# R7FA8M1AH register map
Vendor: Renesas; Series: RA8; File version: 1.2
CPU: CM85 r0p0, little endian, MPU, FPU, VTOR, 4 interrupt priority bits
Registers are 32-bit, read-write, reset 0x0 unless marked. A register's access mark holds for its fields unless they carry their own. Offsets are from the block's base; [hi:lo] are bit positions; {n}, {i} and the like mark numbered series; 'fields as' and 'values as' point back to an identical list.

## DRW — 2D Drawing Engine
Base 0x40344000
Same registers: DRW_NS 0x50344000
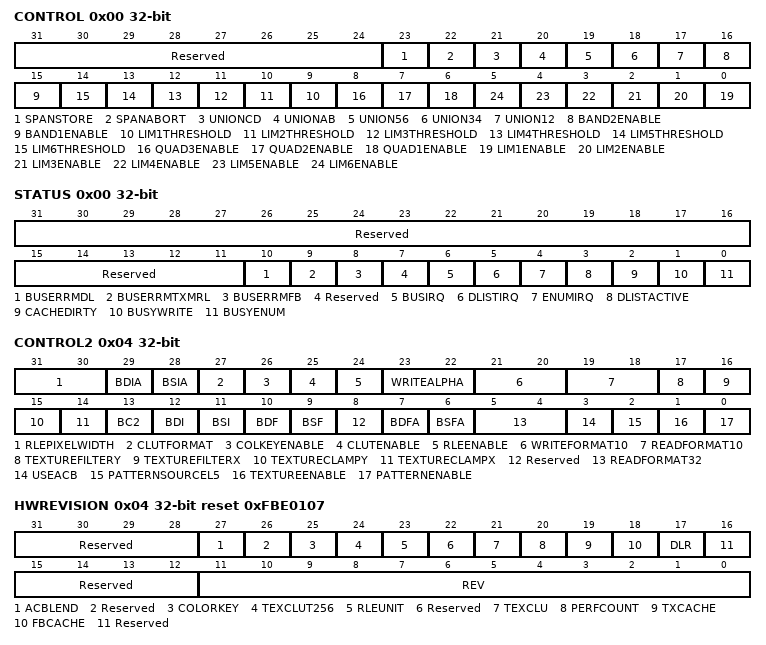
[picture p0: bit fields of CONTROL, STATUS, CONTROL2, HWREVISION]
0x00 CONTROL wo — Geometry Control Register
  [31:24] Reserved — The write value should be 00000000.
  [23] SPANSTORE — Nextline span start is always equal or left to current-line span start
    0=disabled; 1=enabled
  [22] SPANABORT — Shape is horizontally convex, only a single span per scanline
    0=disabled; 1=enabled
  [21] UNIONCD — Combine outputs C & D as union (output is final)
    0=minimum/intersect; 1=maximum/union
  [20] UNIONAB — Combine outputs A & B as union (output is called C)
    0=minimum/intersect; 1=maximum/union
  [19] UNION56 — Combine limter 5 & 6 as union (output is called D)
    0=minimum/intersect; 1=maximum/union
  [18] UNION34 — Combine limter 3 & 4 as union (output is called B)
    0=minimum/intersect; 1=maximum/union
  [17] UNION12 — Combine limter 1 & 2 as union (output is called A)
    0=minimum/intersect; 1=maximum/union
  [16] BAND2ENABLE — Enable band postprocess for limiter 1 (see L1BAND)
    0=disabled; 1=enabled
  [15] BAND1ENABLE — Enable band postprocess for limiter 1 (see L1BAND)
    0=disabled; 1=enabled
  [n+8] LIM{n}THRESHOLD (n=1..6) — Enable limiter {n} threshold mode
    0=disabled; 1=enabled
  [8] QUAD3ENABLE — Enable quadratic coupling of limiters 5 and 6
    0=disabled; 1=enabled
  [7] QUAD2ENABLE — Enable quadratic coupling of limiters 3 and 4
    0=disabled; 1=enabled
  [6] QUAD1ENABLE — Enable quadratic coupling of limiters 1 and 2
    0=disabled; 1=enabled
  [n-1] LIM{n}ENABLE (n=1..6) — Enable limiter {n}
    0=disabled; 1=enabled
0x00 STATUS ro (alternate view of CONTROL) — Status Control Register
  [31:16] Reserved — These bits are read as 0000000000000000.
  [15:11] Reserved — These bits are read as 00000.
  [10] BUSERRMDL — display list bus error interrupt triggered
    0=no display list bus error occurred or interrupt disabled; 1=display list bus error interrupt triggered
  [9] BUSERRMTXMRL — texture bus error interrupt triggered
    0=no texture bus error occurred or interrupt disabled; 1=texture bus error interrupt triggered
  [8] BUSERRMFB — framebuffer bus error interrupt triggered
    0=no framebuffer bus error occured or interrupt disabled; 1=framebuffer bus error interrupt triggered
  [7] Reserved — This bit is read as 0.
  [6] BUSIRQ — bus error interrupt triggered
    0=no bus error occurred or interrupt disabled; 1=bus error interrupt triggered
  [5] DLISTIRQ — display list finished interrupt triggered
    0=display list not finished or interrupt disabled; 1=display list finished interrupt triggered
  [4] ENUMIRQ — enumeration finished interrupt triggered
    0=enumeration not finished or interrupt disabled; 1=enumeration finished interrupt triggered
  [3] DLISTACTIVE — Display list reader status
    0=display list reader is idle; 1=display list reader busy, no direct write access to registers allowed
  [2] CACHEDIRTY — Framebuffer cache status
    0=framebuffer cache is not dirty; 1=framebuffer cache is dirty, frame should not be flipped
  [1] BUSYWRITE — Framebuffer writeback status
    0=framebuffer writeback finished; 1=framebuffer writeback busy, framebuffer type can not be changed
  [0] BUSYENUM — Enumeration unit status
    0=enumeration unit idle; 1=enumeration unit busy, new primitive can not be started
0x04 CONTROL2 wo — Surface Control Register
  [31:30] RLEPIXELWIDTH — Texel width for RLE unit
    {v}={v+1} byte per texel (v=0..3)
  [29] BDIA — Blend destination factor inverted in alpha channel (USEACB = 1)
    0=use blend factor as specified through BDFA; 1=invert blend destination factor (1-x)
  [28] BSIA — Blend source factor inverted in alpha channel (USEACB = 1)
    0=use blend factor as specified through BSFA; 1=invert blend source factor (1-x)
  [27] CLUTFORMAT — Format of the CLUT
    0=aRGB(8888); 1=RGB(565)
  [26] COLKEYENABLE — color keying enable
    0=color keying disabled; 1=color keying enabled
  [25] CLUTENABLE
    0=CLUT disabled; 1=CLUT enabled
  [24] RLEENABLE
    0=RLE disabled; 1=RLE enabled
  [23:22] WRITEALPHA — Writeback alpha source for framebufferSet the 'alpha source' for the framebuffer(USEACB = 0)Blend alpha in color 2 instead of framebuffer alpha((USEACB = 1))In not alpha channel blending mode (USEACB = 0):Set the 'alpha source' for the framebuffer.In alpha channel blending mode (USEACB = 1):Blend alpha in color 2 instead of framebuffer alpha00B: BC2A = 1: use alpha from framebuffer as destination (DST_A)else: BC2A = 0: use alpha in color 2 as destination (DST_A)
    0=use alpha from color 2; 1=use source alpha (pixel coverage); 2=use 0.0 as alpha; 3=use alpha from framebuffer
  [21:20] WRITEFORMAT10 — Pixel format of the framebuffer
    0=8bpp a(8)0; 1=16bpp RGB(565); 2=32bpp aRGB(8888); 3=16bpp aRGB(4444)
  [19:18] READFORMAT10 — Pixel format of the texture buffer{READFORMAT32,READFORMAT10}0000: 8 bpp a(8)0001: 16 bpp RGB(565)0010: 32 bpp aRGB(8888)0011: 16 bpp aRGB(4444)0100: 16 bpp aRGB(1555)0101: 8 bpp aCLUT(44) 4 bit alpha and 4 bit indexed color1001: 8 bpp CLUT(8)/I(8), 8 bit indexed color/luminance1010: 4 bpp CLUT(4)/I(4), 4 bit indexed color/luminance1011: 2 bpp CLUT(2)/I(2), 2 bit indexed color/luminance 1100: 1 bpp CLUT(1)/I(1), 1 bit indexed color/luminance
    0=8 bpp a(8) (READFORMAT32=00) / 16 bpp aRGB(1555) (READFORMAT32=01) / 1 bpp CLUT(1)/I(1), 1 bit indexed color/luminance (READFORMAT32=11); 1=16 bpp RGB(565) (READFORMAT32=00) / 8 bpp aCLUT(44) 4 bit alpha and 4 bit indexed color (READFORMAT32=01) / 8 bpp CLUT(8)/I(8), 8 bit indexed color/luminance (READFORMAT32=10); 2=32 bpp aRGB(8888) (READFORMAT32=00) / 4 bpp CLUT(4)/I(4), 4 bit indexed color/luminance (READFORMAT32=10); 3=16 bpp aRGB(4444) (READFORMAT32=00) / 2 bpp CLUT(2)/I(2), 2 bit indexed color/luminance (READFORMAT32=10)
  [17] TEXTUREFILTERY — Linear filtering on texture V axis
    0=no filtering on texture V axis; 1=linear filtering on texture V axis
  [16] TEXTUREFILTERX — Linear filtering on texture U axis
    0=no filtering on texture U axis; 1=linear filtering on texture U axis
  [15] TEXTURECLAMPY — Calculating V limiter outside use textureThe bit describes what happens if the V limiter (y direction in texture space) calculates a V value outside of the used texture
    0=Texture wrap mode: The integer part of the calculated value from the v limiter is anded with TEXVMASK. This results in a repetition of the texture in y/v direction.; 1=Texture clamp mode: The texture color at the border of the texture is taken. This results in a repetition of the texture border color in y/v direction.
  [14] TEXTURECLAMPX — Calculating U limiter outside use textureThe bit describes what happens if the U limiter (x direction in texture space) calculates a U value outside of the used texture
    0=Texture wrap mode: The integer part of the calculated value from the u limiter is anded with TEXUMASK. This results in a repetition of the texture in x/u direction.; 1=Texture clamp mode: The texture color at the border of the texture is taken. This results in a repetition of the texture border color in x/u direction.
  [13] BC2 — Blend color 2 instead of framebuffer pixel
    0=use pixel from framebuffer as destination (DST); 1=use color 2 as destination (DST)
  [12] BDI — Blend destination factor is inverteddst factor will be inverted (meaning 1-a or 1-1 depending on BDF)
    0=use blend factor as specified through BDF; 1=invert blend destinationfactor (1-x)
  [11] BSI — Blend source factor is invertedsrc factor will be inverted (meaning 1-a or 1-1 depending on BSF)
    0=use blend factor as specified through BSF; 1=invert blend source factor (1-x)
  [10] BDF — Blend destination factordst factor is alpha (factor is 1 per default)
    0=use 1.0 as blend destination factor; 1=use alpha as blend destination factor
  [9] BSF — Blend source factorsrc factor is alpha (factor is 1 per default)
    0=use 1.0 as blend source factor; 1=use alpha as blend source factor
  [8] Reserved — The write value should be 0.
  [7] BDFA — Blend destinetion factor for alpha channel in alpha channel blending mode (USEACB = 1)
    0=use 1.0 as blend destination factor for alpha channel; 1=use alpha as blend destination factor for alpha channel
  [6] BSFA — Blend source factor for alpha channel in alpha channel blending mode (USEACB = 1)
    0=use 1.0 as blend source factor for alpha channel; 1=use alpha as blend source factor for alpha channel
  [5:4] READFORMAT32 — Bit 4 and 3 of the texture buffer format.See READFORMAT above for description
  [3] USEACB — Alpha blend mode
    0=use WRITEALPHA[1:0] mode; 1=use full alpha channel blending mode
  [2] PATTERNSOURCEL5 — Limiter 5 is used as pattern index instead of the default U limiter.Limiter 5 can be combined with limiter 6 to form a quadratic limiter which can be used to make quadratic pattern functions to draw radial patterns.
  [1] TEXTUREENABLE — Pixel source is read from texture and used as an alpha to blend between COLOR1 and COLOR2
    0=disabled texture; 1=enabled texture
  [0] PATTERNENABLE — Pixel source is a pattern color (blend of COLOR1 and COLOR2 depending on PATTERN and pattern index)
    0=disabled pattern; 1=enabled pattern
0x04 HWREVISION ro reset 0xFBE0107 (reset mask 0xFFFFF000) (alternate view of CONTROL2) — Hardware Version and Feature Set ID Register
  [31:28] Reserved — These bits are read as 0000.
  [27] ACBLEND — Alpha channel blending feature
    0=Alpha channel blending unavailable; 1=Alpha channel blending available
  [26] Reserved — This bit is read as 1.
  [25] COLORKEY — Colorkey feature
    0=Colorkey unavailable; 1=Colorkey available
  [24] TEXCLUT256 — Texture CLUT feature
    0=Texture CLUT unavailable; 1=Texture CLUT available
  [23] RLEUNIT — RLE unit feature
    0=RLE unit unavailable; 1=RLE unit available
  [22] Reserved — This bit is read as 0.
  [21] TEXCLU — Texture CLUT with 16 or 256 entries feature
    0=Texture CLUT with 16 or 256 entries unavailable; 1=Texture CLUT with 16 or 256 entries available
  [20] PERFCOUNT — Two performance counter feature
    0=Two performance counter unavailable; 1=Two performance counter available
  [19] TXCACHE — Texture cache feature
    0=Texture cache unavailable; 1=Texture cache available
  [18] FBCACHE — Framebuffer cache feature
    0=Framebuffer cache unavailable; 1=Framebuffer cache available
  [17] DLR — Display list reader feature
    0=Display list reader unavailable; 1=Display list reader available
  [16] Reserved — This bit is read as 0.
  [15:12] Reserved — These bits are read as 0000.
  [11:0] REV — Revision number
{0xC+4i} L{i}START (i=1..6) wo — Limiter {i} Start Value Register
  [31:0] LSTART — Start value of the n'th limiter(n=1-6)
{0x24+4i} L{i}XADD (i=1..6) wo — Limiter {i} X-Axis Increment Register
  [31:0] LXADD — X-axis increment
{0x3C+4i} L{i}YADD (i=1..6) wo — Limiter {i} Y-Axis Increment Register
  [31:0] LYADD — Y-axis increment
{0x54+4i} L{i}BAND (i=1..2) wo — Limiter {i} Band Width Parameter Register
  [31:0] LBAND — Limiter m band width parameter
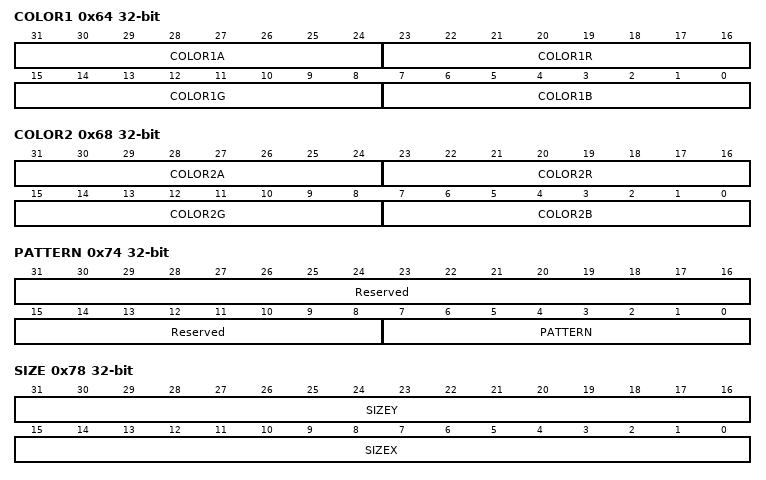
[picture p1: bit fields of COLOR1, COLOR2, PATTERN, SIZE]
0x64 COLOR1 wo — Base Color Register
  [31:24] COLOR1A — Alpha channel of color 1(0x00: transparent. . . 0xFF: opaque)
  [23:16] COLOR1R — Red channel of color 1
  [15:8] COLOR1G — Green channel of color 1
  [7:0] COLOR1B — Blue channel of color 1
0x68 COLOR2 wo — Secondary Color Register
  [31:24] COLOR2A — Alpha channel of color 2(0x00: transparent. . . 0xFF: opaque)
  [23:16] COLOR2R — Red channel of color 2
  [15:8] COLOR2G — Green channel of color 2
  [7:0] COLOR2B — Blue channel of color 2
0x74 PATTERN wo
  [31:16] Reserved — The write value should be 0000000000000000.
  [15:8] Reserved — The write value should be 00000000.
  [7:0] PATTERN — Bitmap of the pattern
0x78 SIZE wo — Bounding Box Dimension Register
  [31:16] SIZEY — Height of the bounding box in pixelsvalid range: 0 to 1024
  [15:0] SIZEX — Width of the bounding box in pixelsvalid range: 0 to 1024
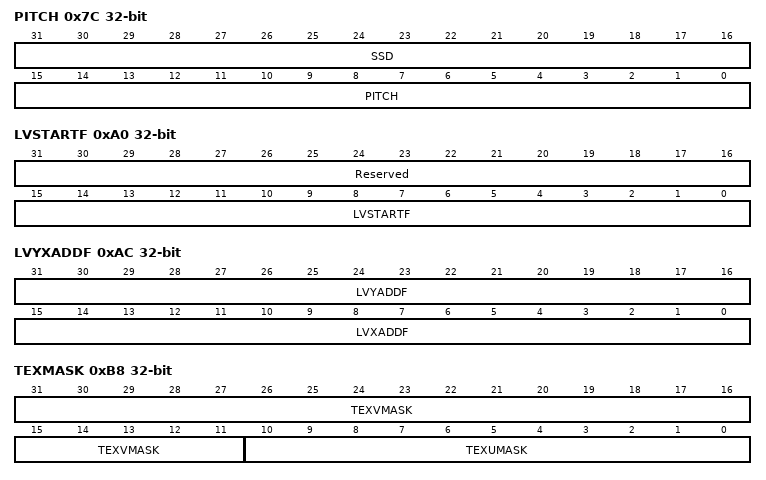
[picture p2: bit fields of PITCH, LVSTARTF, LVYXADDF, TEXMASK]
0x7C PITCH wo — Framebuffer Pitch And Spanstore Delay Register
  [31:16] SSD — Spanstore delay
  [15:0] PITCH — pitch of the framebuffer. A negative width can be used to render bottom-up instead of top-down
0x80 ORIGIN wo — Framebuffer Base Address Register
  [31:0] ORIGIN — Address of the first pixel in framebuffer
0x90 LUSTART wo — U Limiter Start Value Register
  [31:0] LUSTART — U limiter start value
0x94 LUXADD wo — U Limiter X-Axis Increment Register
  [31:0] LUXADD — U limiter x-axis increment
0x98 LUYADD wo — U Limiter Y-Axis Increment Register
  [31:0] LUYADD — U limiter y-axis increment
0x9C LVSTARTI wo — V Limiter Start Value Integer Part Register
  [31:0] LVSTARTI — V limiter start value integer part
0xA0 LVSTARTF wo — V Limiter Start Value Fractional Part Register
  [31:16] Reserved — The write value should be 0000000000000000.
  [15:0] LVSTARTF — V limiter start value fractional part
0xA4 LVXADDI wo — V Limiter X-Axis Increment Integer Part Register
  [31:0] LVXADDI — V limiter x-axis increment integer part
0xA8 LVYADDI wo — V Limiter Y-Axis Increment Integer Part Register
  [31:0] LVYADDI — V limiter y-axis increment integer part
0xAC LVYXADDF wo — V Limiter Increment Fractional Parts Register
  [31:16] LVYADDF — V y limiter increment fractional part
  [15:0] LVXADDF — V xlimiter increment fractional part
0xB4 TEXPITCH wo — Texels Per Texture Line Register
  [31:0] TEXPITCH — Texels per texture linevalid range: 0 to 2048
0xB8 TEXMASK wo — Texture Size or Texture Address Mask Register
  [31:11] TEXVMASK — V maskSet TEXVMASK[20:0] = TEXPITCH * (texture_height - 1).In texture wrapping mode (CONTROL2.TEXTURECLAMPY = 0): texture_height must be a power of 2In texture clamping mode (CONTROL2.TEXTURECLAMPY = 1):all heights up to 1024 are allowed.
  [10:0] TEXUMASK — U maskSet TEXUMASK[10:0] = texture_width -1In texture wrapping mode (CONTROL2.TEXTURECLAMPX = 0): texture_width must be a power of 2.In texture clamping mode (CONTROL2.TEXTURECLAMPX = 1):all widths up to 2048 are allowed.
0xBC TEXORIGIN wo — Texture Base Address Register
  [31:0] TEXORIGIN — Texture base address
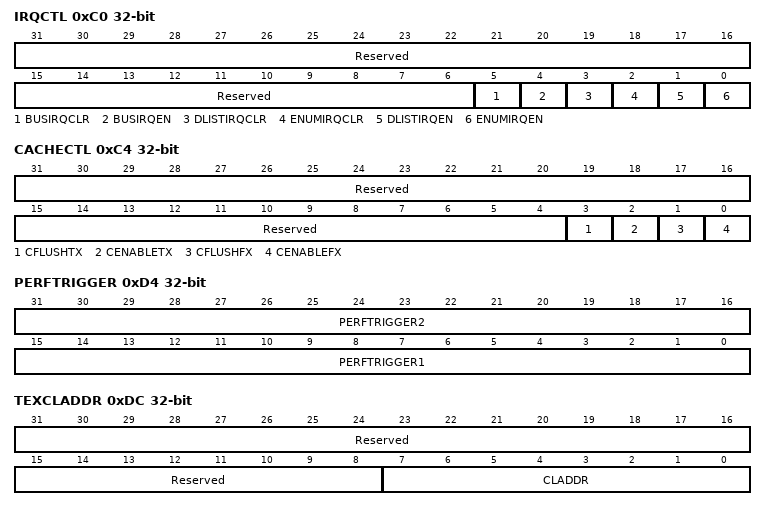
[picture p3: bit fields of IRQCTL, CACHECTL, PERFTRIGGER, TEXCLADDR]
0xC0 IRQCTL wo — Interrupt Control Register
  [31:16] Reserved — The write value should be 0000000000000000.
  [15:6] Reserved — The write value should be 0000000000.
  [5] BUSIRQCLR — Clear bus error interrupt BUSIRQ
    0=no BUSIRQCLR clear; 1=clear BUSIRQCLR
  [4] BUSIRQEN — BUSIRQ interrupt mask enable
    0=disable (mask) BUSIRQ; 1=enable (unmask) BUSIRQ
  [3] DLISTIRQCLR — Clear display list interrupt DLISTIRQ
    0=no DLISTRQCLR clear; 1=clear DLISTRQCLR
  [2] ENUMIRQCLR — Clear enumeration interrupt ENUMIRQ
    0=no ENUMIRQCLR clear; 1=clear ENUMIRQCLR
  [1] DLISTIRQEN — DLISTIRQ interrupt mask enable
    0=disable (mask) DLISTIRQ; 1=enable (unmask) DLISTIRQ
  [0] ENUMIRQEN — ENUMIRQ interrupt mask enable
    0=disable (mask) ENUMIRQ; 1=enable (unmask) ENUMIRQ
0xC4 CACHECTL wo — Cache Control Register
  [31:16] Reserved — The write value should be 0000000000000000.
  [15:4] Reserved — The write value should be 000000000000.
  [3] CFLUSHTX — Flush texture cache
    0=do not flush the texture cache; 1=flush the texture cache
  [2] CENABLETX — Texture cache enable
    0=disable the texture cache; 1=enable the texture cache
  [1] CFLUSHFX — Flush framebuffer cache
    0=do not flush the framebuffer cache; 1=flush the framebuffer cache
  [0] CENABLEFX — Framebuffer cache enable
    0=disable the framebuffer cache; 1=enable the framebuffer cache
0xC8 DLISTSTART wo — Display List Start Address Register
  [31:0] DLISTSTART — Display list start address
{0xC8+4i} PERFCOUNT{i} (i=1..2) — Performance Counter {i}
  [31:0] PERFCOUNTk — Counter value.The counter is reset by writing PERFCOUNT = 0000 0000H.
0xD4 PERFTRIGGER wo — Performance Counters Control Register
  [31:16] PERFTRIGGER2 — Selects the internal event that will increment PERFCOUNT2 register
    0=disable performance counter; 1=2D Drawing Engine active cycles; 2=framebuffer read access; 3=framebuffer write access; 4=texture read access; 5=invisible pixels (enumerated but selected with alpha 0percent); 6=invisible pixels while internal FIFO is empty (lost cycles); 7=display list reader active cycles; 8=framebuffer read hits; 9=framebuffer read misses; 10=framebuffer write hits; 11=framebuffer write misses; 12=texture read hits; 13=texture read misses; 31=every clock cycle (for use as timer); other=others (Setting prohibited)
  [15:0] PERFTRIGGER1 — Selects the internal event that will increment PERFCOUNT1 register.
    values as PERFTRIGGER2
0xDC TEXCLADDR wo — CLUT Start Address Register
  [31:16] Reserved — The write value should be 0000000000000000.
  [15:8] Reserved — The write value should be 00000000.
  [7:0] CLADDR — Texture CLUT start address for indexed texture format
0xE0 TEXCLDATA wo — CLUT Data Register
  [31:0] CLDATA — Texture CLUT data for Indexed texture format
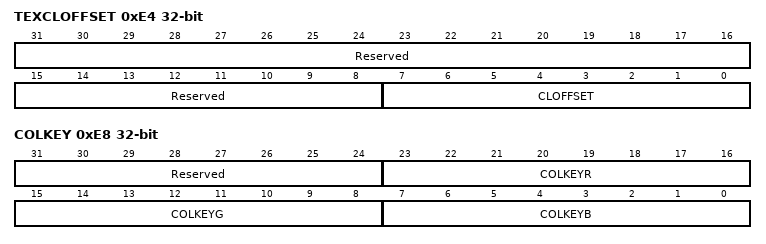
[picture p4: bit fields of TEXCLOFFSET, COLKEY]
0xE4 TEXCLOFFSET wo — CLUT Offset Register
  [31:16] Reserved — The write value should be 0000000000000000.
  [15:8] Reserved — The write value should be 00000000.
  [7:0] CLOFFSET — Texture CLUT offset for Indexed texture format. CLOFFSET[7:0] is or'ed with the original index
0xE8 COLKEY wo — Color Key Register
  [31:24] Reserved — The write value should be 00000000.
  [23:16] COLKEYR — Red channel of color key
  [15:8] COLKEYG — Green channel of color key
  [7:0] COLKEYB — Blue channel of color key
